# GD32F5HC register map
File version: 1.0
CPU: CM33 r0p4, little endian, MPU, FPU, 4 interrupt priority bits
Registers are 32-bit, read-write, reset 0x0 unless marked. A register's access mark holds for its fields unless they carry their own. Offsets are from the block's base; [hi:lo] are bit positions; {n}, {i} and the like mark numbered series.

## DMA0 — DMA controller
Base 0x40026000
Same registers: DMA1 0x40026400, SEC_DMA0 0x50026000, SEC_DMA1 0x50026400
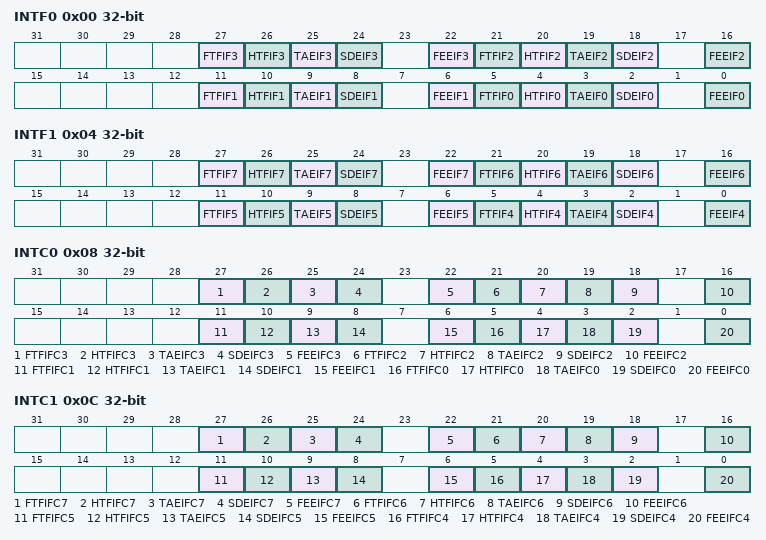
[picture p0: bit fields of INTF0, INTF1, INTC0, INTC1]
0x00 INTF0 ro — Interrupt flag register 0
  [27] FTFIF3 — Full Transfer finish flag of channel 3
  [26] HTFIF3 — Half transfer finish flag of channel 3
  [25] TAEIF3 — Transfer access error flag of channel 3
  [24] SDEIF3 — Single data mode exception of channel 3
  [22] FEEIF3 — FIFO error and exception of channel 3
  [21] FTFIF2 — Full Transfer finish flag of channel 2
  [20] HTFIF2 — Half transfer finish flag of channel 2
  [19] TAEIF2 — Transfer access error flag of channel 2
  [18] SDEIF2 — Single data mode exception of channel 2
  [16] FEEIF2 — FIFO error and exception of channel 2
  [11] FTFIF1 — Full Transfer finish flag of channel 1
  [10] HTFIF1 — Half transfer finish flag of channel 1
  [9] TAEIF1 — Transfer access error flag of channel 1
  [8] SDEIF1 — Single data mode exception of channel 1
  [6] FEEIF1 — FIFO error and exception of channel 1
  [5] FTFIF0 — Full Transfer finish flag of channel 0
  [4] HTFIF0 — Half transfer finish flag of channel 0
  [3] TAEIF0 — Transfer access error flag of channel 0
  [2] SDEIF0 — Single data mode exception of channel 0
  [0] FEEIF0 — FIFO error and exception of channel 0
0x04 INTF1 ro — Interrupt flag register 1
  [27] FTFIF7 — Full Transfer finish flag of channel 7
  [26] HTFIF7 — Half transfer finish flag of channel 7
  [25] TAEIF7 — Transfer access error flag of channel 7
  [24] SDEIF7 — Single data mode exception of channel 7
  [22] FEEIF7 — FIFO error and exception of channel 7
  [21] FTFIF6 — Full Transfer finish flag of channel 6
  [20] HTFIF6 — Half transfer finish flag of channel 6
  [19] TAEIF6 — Transfer access error flag of channel 6
  [18] SDEIF6 — Single data mode exception of channel 6
  [16] FEEIF6 — FIFO error and exception of channel 6
  [11] FTFIF5 — Full Transfer finish flag of channel 5
  [10] HTFIF5 — Half transfer finish flag of channel 5
  [9] TAEIF5 — Transfer access error flag of channel 5
  [8] SDEIF5 — Single data mode exception of channel 5
  [6] FEEIF5 — FIFO error and exception of channel 5
  [5] FTFIF4 — Full Transfer finish flag of channel 4
  [4] HTFIF4 — Half transfer finish flag of channel 4
  [3] TAEIF4 — Transfer access error flag of channel 4
  [2] SDEIF4 — Single data mode exception of channel 4
  [0] FEEIF4 — FIFO error and exception of channel 4
0x08 INTC0 wo — Interrupt flag clear register 0
  [27] FTFIFC3 — Clear bit for Full transfer finish flag of channel 3
  [26] HTFIFC3 — Clear bit for half transfer finish flag of channel 3
  [25] TAEIFC3 — Clear bit for transfer access error flag of channel 3
  [24] SDEIFC3 — Clear bit for single data mode exception of channel 3
  [22] FEEIFC3 — Clear bit for FIFO error and exception of channel 3
  [21] FTFIFC2 — Clear bit for Full transfer finish flag of channel 2
  [20] HTFIFC2 — Clear bit for half transfer finish flag of channel 2
  [19] TAEIFC2 — Clear bit for transfer access error flag of channel 2
  [18] SDEIFC2 — Clear bit for single data mode exception of channel 2
  [16] FEEIFC2 — Clear bit for FIFO error and exception of channel 2
  [11] FTFIFC1 — Clear bit for Full transfer finish flag of channel 1
  [10] HTFIFC1 — Clear bit for half transfer finish flag of channel 1
  [9] TAEIFC1 — Clear bit for transfer access error flag of channel 1
  [8] SDEIFC1 — Clear bit for single data mode exception of channel 1
  [6] FEEIFC1 — Clear bit for FIFO error and exception of channel 1
  [5] FTFIFC0 — Clear bit for Full transfer finish flag of channel 0
  [4] HTFIFC0 — Clear bit for half transfer finish flag of channel 0
  [3] TAEIFC0 — Clear bit for transfer access error flag of channel 0
  [2] SDEIFC0 — Clear bit for single data mode exception of channel 0
  [0] FEEIFC0 — Clear bit for FIFO error and exception of channel 0
0x0C INTC1 wo — Interrupt flag clear register 1
  [27] FTFIFC7 — Clear bit for Full transfer finish flag of channel 7
  [26] HTFIFC7 — Clear bit for half transfer finish flag of channel 7
  [25] TAEIFC7 — Clear bit for transfer access error flag of channel 7
  [24] SDEIFC7 — Clear bit for single data mode exception of channel 7
  [22] FEEIFC7 — Clear bit for FIFO error and exception of channel 7
  [21] FTFIFC6 — Clear bit for Full transfer finish flag of channel 6
  [20] HTFIFC6 — Clear bit for half transfer finish flag of channel 6
  [19] TAEIFC6 — Clear bit for transfer access error flag of channel 6
  [18] SDEIFC6 — Clear bit for single data mode exception of channel 6
  [16] FEEIFC6 — Clear bit for FIFO error and exception of channel 6
  [11] FTFIFC5 — Clear bit for Full transfer finish flag of channel 5
  [10] HTFIFC5 — Clear bit for half transfer finish flag of channel 5
  [9] TAEIFC5 — Clear bit for transfer access error flag of channel 5
  [8] SDEIFC5 — Clear bit for single data mode exception of channel 5
  [6] FEEIFC5 — Clear bit for FIFO error and exception of channel 5
  [5] FTFIFC4 — Clear bit for Full transfer finish flag of channel 4
  [4] HTFIFC4 — Clear bit for half transfer finish flag of channel 4
  [3] TAEIFC4 — Clear bit for transfer access error flag of channel 4
  [2] SDEIFC4 — Clear bit for single data mode exception of channel 4
  [0] FEEIFC4 — Clear bit for FIFO error and exception of channel 4
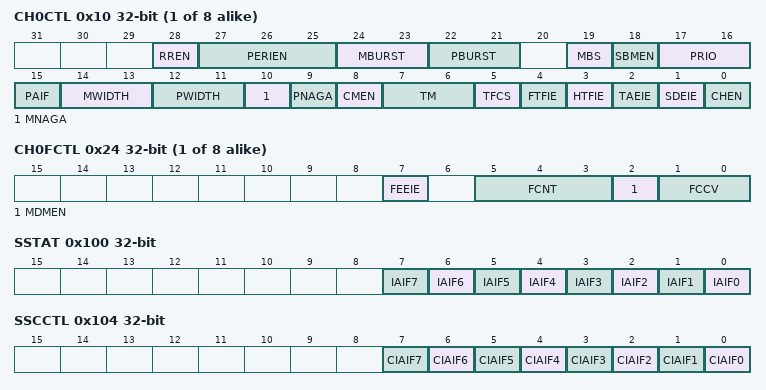
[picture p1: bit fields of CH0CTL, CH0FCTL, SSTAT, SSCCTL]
{0x10+0x18*i} CH{i}CTL (i=0..7) — Channel {i} control register
  [28] RREN — Round-robin
  [27:25] PERIEN — Peripheral enable
  [24:23] MBURST — Transfer burst type of memory
  [22:21] PBURST — Transfer burst type of peripheral
  [19] MBS — Memory buffer select
  [18] SBMEN — Switch-buffer mode enable
  [17:16] PRIO — Priority level
  [15] PAIF — Peripheral address increment fixed
  [14:13] MWIDTH — Transfer width of memory
  [12:11] PWIDTH — Transfer width of peripheral
  [10] MNAGA — Next address generation algorithm of memory
  [9] PNAGA — Next address generation algorithm of peripheral
  [8] CMEN — Circulation mode enable
  [7:6] TM — Transfer mode
  [5] TFCS — Transfer flow controller select
  [4] FTFIE — Enable bit for full transfer finish interrupt
  [3] HTFIE — Enable bit for half transfer finish interrupt
  [2] TAEIE — Enable bit for tranfer access error interrupt
  [1] SDEIE — Enable bit for single data mode exception interrupt
  [0] CHEN — Channel enable
{0x14+0x18*i} CH{i}CNT (i=0..7) — Channel {i} counter register
  [15:0] CNT — Transfer counter
{0x18+0x18*i} CH{i}PADDR (i=0..7) — Channel {i} peripheral base address register
  [31:0] PADDR — Peripheral base address
{0x1C+0x18*i} CH{i}M0ADDR (i=0..7) — Channel {i} memory 0 base address register
  [31:0] M0ADDR — Memory 0 base address
{0x20+0x18*i} CH{i}M1ADDR (i=0..7) — Channel {i} memory 1 base address register
  [31:0] M1ADDR — Memory 1 base address
{0x24+0x18*i} CH{i}FCTL access per field (i=0..7) — Channel {i} FIFO control register
  [7] FEEIE rw — Enable bit for FIFO error and exception interrupt
  [5:3] FCNT ro — FIFO counter
  [2] MDMEN rw — Multi-data mode enable
  [1:0] FCCV rw — FIFO counter critical value
0x100 SSTAT ro — Security status register
  [n] IAIF{n} (n=0..7) — Channel {n} illegal access interrupt flag
0x104 SSCCTL wo — Security status register
  [n] CIAIF{n} (n=0..7) — Stream {n} clear illegal access interrupt flag
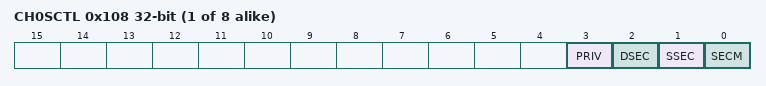
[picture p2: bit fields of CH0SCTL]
{0x108+4i} CH{i}SCTL wo (i=0..7) — Channel {i} security control register
  [3] PRIV — Privileged mode
  [2] DSEC — Security of the DMA transfer to the destination
  [1] SSEC — Security of the DMA transfer from the source
  [0] SECM — Secure mode
